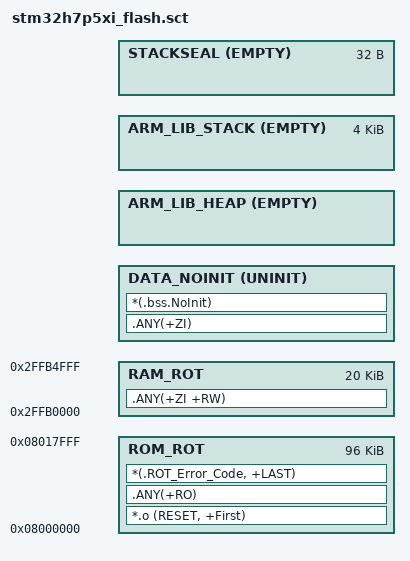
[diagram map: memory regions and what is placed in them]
#! armclang -E --target=arm-arm-none-eabi -march=armv7-m -xc
; command above MUST be in first line (no comment above!)

; ******************************************************************************
; * @file    stm32h7p5xi_flash.sct
; * @brief   Linker File
; ******************************************************************************
; * @attention
; *
; * Copyright (c) 2026 STMicroelectronics.
; * All rights reserved.
; *
; * This software is licensed under terms that can be found in the LICENSE file
; * in the root directory of this software component.
; * If no LICENSE file comes with this software, it is provided AS-IS.
; *
; ******************************************************************************

/* Do not edit ROM_ROT_xxxxxx definitions, updated by the provisioning scripts */
#define ROM_ROT_ADDRESS 0x8000000
#define ROM_ROT_SIZE    0x18000

/* RAM_ROT_xxxx definitions shall be aligned with SRAM_ROT_xxxx definitions of region_defs.h */
#define RAM_ROT_ADDRESS 0x2FFB0000
#define RAM_ROT_SIZE    0x5000

#define __HEAP_SIZE     0x0
#define __STACK_SIZE    0x1000

ROM_ROT ROM_ROT_ADDRESS
{
  ROM_ROT ROM_ROT_ADDRESS ROM_ROT_SIZE
  {
    /* Vector table at start of ROM */
    *.o (RESET, +First)

    /* All RO sections */
    .ANY(+RO)

    /* Explicitly place the .ROT_Error_Code section at the end */
    *(.ROT_Error_Code, +LAST)
  }

  RAM_ROT RAM_ROT_ADDRESS RAM_ROT_SIZE
  {
    /* RW and ZI data placed in RAM_ROT */
    .ANY(+ZI +RW)
  }

  /* Section .bss.NoInit / .noinit equivalent (if used) */
  DATA_NOINIT +0 ALIGN 32 UNINIT
  {
    .ANY(+ZI)
    *(.bss.NoInit)
  }

  /* HEAP */
  ARM_LIB_HEAP AlignExpr(+0, 8) EMPTY __HEAP_SIZE
  {
  }

  /* STACK */
  ARM_LIB_STACK AlignExpr(+0, 8) EMPTY __STACK_SIZE
  {
  }

  /* STACK SEAL region for Cortex-M85 stack protection
   * Needed because startup_stm32v873xx.o references Image$$STACKSEAL$$ZI$$Base
   */
  STACKSEAL AlignExpr(+0, 8) EMPTY 0x20
  {
  }
}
